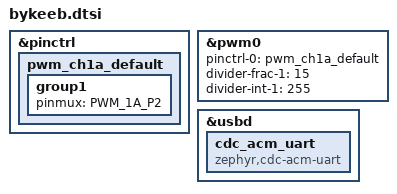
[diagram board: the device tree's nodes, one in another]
/*
 * Copyright (c) 2025, ykz89
 * SPDX-License-Identifier: MIT
 */

#include <dt-bindings/pinctrl/rpi-pico-rp2040-pinctrl.h>
#include <rpi_pico/rp2040.dtsi>
#include "bykeeb-pinctl.dtsi"

&pinctrl {
    // for audio buzzer
    pwm_ch1a_default: pwm_ch1a_default {
	    group1 {
		    pinmux = <PWM_1A_P2>;
	    };
    };
};

&pwm0 {
    status = "okay";
    pinctrl-0 = <&pwm_ch1a_default>;
    pinctrl-names = "default";
    divider-frac-1 = <15>;  // divider-frac-1 instead of divider-frac-0
    divider-int-1 = <255>;  // divider-int-1 instead of divider-int-0
};

&usbd {
    status = "okay";
    cdc_acm_uart: cdc_acm_uart {
        compatible = "zephyr,cdc-acm-uart";
    };
};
